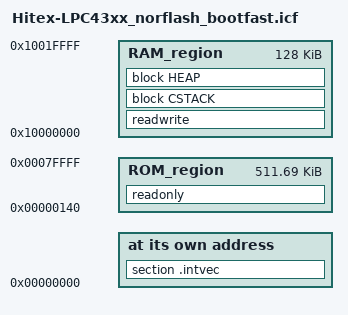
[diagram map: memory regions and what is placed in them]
/*###ICF### Section handled by ICF editor, don't touch! ****/
/*-Editor annotation file-*/
/* IcfEditorFile="$TOOLKIT_DIR$\config\ide\IcfEditor\cortex_v1_0.xml" */
/*-Specials-*/
define symbol __ICFEDIT_intvec_start__ = 0x00000000;
/*-Memory Regions-*/
define symbol __ICFEDIT_region_ROM_start__ = 0x00000140;
define symbol __ICFEDIT_region_ROM_end__   = 0x0007FFFF;
define symbol __ICFEDIT_region_RAM_start__ = 0x10000000;
define symbol __ICFEDIT_region_RAM_end__   = 0x1001FFFF;
/*-Sizes-*/
define symbol __ICFEDIT_size_cstack__ = 0x400;
define symbol __ICFEDIT_size_heap__   = 0x200;
/**** End of ICF editor section. ###ICF###*/

/* define symbol __CRP_start__   = 0x000002FC; */
/* define symbol __CRP_end__     = 0x000002FF; */

define memory mem with size = 4G;
define region ROM_region   = mem:[from __ICFEDIT_region_ROM_start__   to __ICFEDIT_region_ROM_end__];
define region RAM_region   = mem:[from __ICFEDIT_region_RAM_start__   to __ICFEDIT_region_RAM_end__];
/* define region CRP_region   = mem:[from  __CRP_start__ to __CRP_end__]; */

define block CSTACK    with alignment = 8, size = __ICFEDIT_size_cstack__   { };
define block HEAP      with alignment = 8, size = __ICFEDIT_size_heap__     { };

initialize by copy { readwrite,
                          object lpc43xx_gpio.o,
                          object lpc43xx_scu.o,
                          object lpc43xx_cgu.o,
                          object lpc43xx_emc.o,
                          object Hitex_Fast_Startup.o,
                          object spifi_rom_api.o(spifi_drv_M4.lib),
                          object amic.o(spifi_drv_M4.lib),
                          object atmel.o(spifi_drv_M4.lib),
                          object chi.o(spifi_drv_M4.lib),
                          object eon.o(spifi_drv_M4.lib),
                          object esmt.o(spifi_drv_M4.lib),
                          object giga.o(spifi_drv_M4.lib),
                          object macronix.o(spifi_drv_M4.lib),
                          object numonyx.o(spifi_drv_M4.lib),
                          object spansion.o(spifi_drv_M4.lib),
                          object sst.o(spifi_drv_M4.lib),
                          object winbond.o(spifi_drv_M4.lib)
                    };
do not initialize  { section .noinit };

place at address mem:__ICFEDIT_intvec_start__ { section .intvec };

place in RAM_region     { readwrite,
                          block CSTACK, block HEAP
                          };
place in ROM_region     { readonly };

/* place in CRP_region  { section .crp}; */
